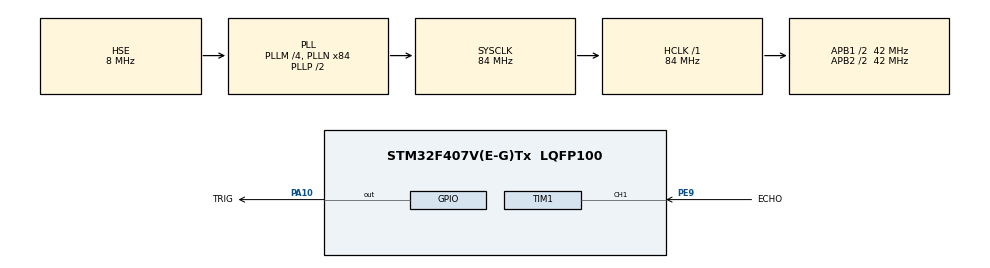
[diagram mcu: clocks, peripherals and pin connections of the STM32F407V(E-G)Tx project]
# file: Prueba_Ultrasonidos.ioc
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Mcu.Family=STM32F4
Mcu.Name=STM32F407V(E-G)Tx
Mcu.Package=LQFP100
NVIC.PriorityGroup=NVIC_PRIORITYGROUP_0
NVIC.TIM1_CC_IRQn=true\:0\:0\:false\:false\:true\:true\:true
PA10.GPIO_Label=TRIG
PA10.Signal=GPIO_Output
PE9.GPIO_Label=ECHO
PE9.Signal=S_TIM1_CH1
PH0-OSC_IN.Mode=HSE-External-Oscillator
PH0-OSC_IN.Signal=RCC_OSC_IN
PH1-OSC_OUT.Mode=HSE-External-Oscillator
PH1-OSC_OUT.Signal=RCC_OSC_OUT
ProjectManager.HeapSize=0x200
ProjectManager.StackSize=0x400
ProjectManager.TargetToolchain=STM32CubeIDE
RCC.48MHZClocksFreq_Value=24000000
RCC.AHBFreq_Value=84000000
RCC.APB1CLKDivider=RCC_HCLK_DIV2
RCC.APB1Freq_Value=42000000
RCC.APB1TimFreq_Value=84000000
RCC.APB2CLKDivider=RCC_HCLK_DIV2
RCC.APB2Freq_Value=42000000
RCC.APB2TimFreq_Value=84000000
RCC.CortexFreq_Value=84000000
RCC.HCLKFreq_Value=84000000
RCC.HSE_VALUE=8000000
RCC.HSI_VALUE=16000000
RCC.LSE_VALUE=32768
RCC.PLLM=4
RCC.PLLN=84
RCC.PLLQ=7
RCC.PLLSourceVirtual=RCC_PLLSOURCE_HSE
RCC.SYSCLKFreq_VALUE=84000000
RCC.SYSCLKSource=RCC_SYSCLKSOURCE_PLLCLK
RCC.VCOOutputFreq_Value=168000000
SH.S_TIM1_CH1.0=TIM1_CH1,Input_Capture1_from_TI1
TIM1.Channel-Input_Capture1_from_TI1=TIM_CHANNEL_1
TIM1.Period=65535-1
TIM1.Prescaler=84-1
board=STM32F407G-DISC1

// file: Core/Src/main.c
/* USER CODE BEGIN Header */
/**
  ******************************************************************************
  * @file           : main.c
  * @brief          : Main program body
  ******************************************************************************
  * @attention
  *
  * <h2><center>&copy; Copyright (c) 2021 STMicroelectronics.
  * All rights reserved.</center></h2>
  *
  * This software component is licensed by ST under BSD 3-Clause license,
  * the "License"; You may not use this file except in compliance with the
  * License. You may obtain a copy of the License at:
  *                        opensource.org/licenses/BSD-3-Clause
  *
  ******************************************************************************
  */
/* USER CODE END Header */
#include "main.h"

TIM_HandleTypeDef htim1;

void SystemClock_Config(void);
static void MX_GPIO_Init(void);
static void MX_TIM1_Init(void);

/* USER CODE BEGIN 0 */
float dist  = 0;

float calcularDistancia(uint64_t time)
{
	const float Vsonido = 340.0f;	// Velocidad sonido = 340m/s
	float dist = (float)time * Vsonido/2.0f / 10000.0f;	// El 1/10000 es por el cambio de conversion de s a us y de m a cm
	return dist;	// En cm
}

void HAL_TIM_IC_CaptureCallback(TIM_HandleTypeDef *htim)
{
	static uint64_t timeRise = 0, timeFall = 0, timeDif = 0;
	static uint8_t EdgeCapture = 0;	// 0 si va a detectar flanco de subida, 1 si va a detectar falcno de bajada

	if (!EdgeCapture)	// Si se va a detectar el flanco de subida
	{
		EdgeCapture = 1;  // Se cambia para detectar despues el flanco de bajada

		timeRise = HAL_TIM_ReadCapturedValue(htim, TIM_CHANNEL_1);	// Se guarda el instsnte de tiempo en el que se ha alcanzado el flanco de subida

		__HAL_TIM_SET_CAPTUREPOLARITY(htim, TIM_CHANNEL_1, TIM_INPUTCHANNELPOLARITY_FALLING);	// Cambio del tipo de flanco para detectar flancos de bajada
	}
	else	// Si se va a detectar el flanco de bajada
	{
		EdgeCapture = 0;	// Se cambia para detectar otro flanco de subida

		timeFall = HAL_TIM_ReadCapturedValue(htim, TIM_CHANNEL_1);  // Se guarda el instsnte de tiempo en el que se ha alcanzado el flanco de bajada

		__HAL_TIM_SET_COUNTER(htim, 0);	// Se pone a cero el contador de tiempo para la siguiente deteccion del flanco de subida
		__HAL_TIM_SET_CAPTUREPOLARITY(htim, TIM_CHANNEL_1, TIM_INPUTCHANNELPOLARITY_RISING);	// Cambio del tipo de flanco para detectar flancos de subida

		timeDif = timeFall - timeRise;	// El tiempo necesario para calcular la distancia es la resta del tiempo de flancos
		dist = calcularDistancia(timeDif);	// Se calcula la distancia en cm
	}
}

void leerUltrasonido(GPIO_TypeDef* GPIOx, uint16_t GPIO_Pin)
{
	HAL_GPIO_WritePin(GPIOx, GPIO_Pin, 1);	// Activar TRIG
	HAL_Delay(0.01);  // Esperar 10 us = 0.01 ms
	HAL_GPIO_WritePin(GPIOx, GPIO_Pin, 0);	// Desactivar TRIG
}

/* USER CODE END 0 */

int main(void)
{

  /* MCU Configuration--------------------------------------------------------*/

  /* Reset of all peripherals, Initializes the Flash interface and the Systick. */
  HAL_Init();

  /* Configure the system clock */
  SystemClock_Config();

  /* Initialize all configured peripherals */
  MX_GPIO_Init();
  MX_TIM1_Init();
  /* USER CODE BEGIN 2 */
  HAL_TIM_IC_Start_IT(&htim1, TIM_CHANNEL_1);
  /* USER CODE END 2 */

  /* Infinite loop */
  while (1)
  {

    /* USER CODE BEGIN 3 */
	leerUltrasonido(GPIOA, GPIO_PIN_10);	// Leer Ultrasonido conectado a pin A10
	HAL_Delay(100);	// Espera para volver a disparar, NO menor a 100ms !!!

  }
  /* USER CODE END 3 */
}

void SystemClock_Config(void)
{
  RCC_OscInitTypeDef RCC_OscInitStruct = {0};
  RCC_ClkInitTypeDef RCC_ClkInitStruct = {0};

  /** Configure the main internal regulator output voltage
  */
  __HAL_RCC_PWR_CLK_ENABLE();
  __HAL_PWR_VOLTAGESCALING_CONFIG(PWR_REGULATOR_VOLTAGE_SCALE1);
  /** Initializes the RCC Oscillators according to the specified parameters
  * in the RCC_OscInitTypeDef structure.
  */
  RCC_OscInitStruct.OscillatorType = RCC_OSCILLATORTYPE_HSE;
  RCC_OscInitStruct.HSEState = RCC_HSE_ON;
  RCC_OscInitStruct.PLL.PLLState = RCC_PLL_ON;
  RCC_OscInitStruct.PLL.PLLSource = RCC_PLLSOURCE_HSE;
  RCC_OscInitStruct.PLL.PLLM = 4;
  RCC_OscInitStruct.PLL.PLLN = 84;
  RCC_OscInitStruct.PLL.PLLP = RCC_PLLP_DIV2;
  RCC_OscInitStruct.PLL.PLLQ = 7;
  if (HAL_RCC_OscConfig(&RCC_OscInitStruct) != HAL_OK)
  {
    Error_Handler();
  }
  /** Initializes the CPU, AHB and APB buses clocks
  */
  RCC_ClkInitStruct.ClockType = RCC_CLOCKTYPE_HCLK|RCC_CLOCKTYPE_SYSCLK
                              |RCC_CLOCKTYPE_PCLK1|RCC_CLOCKTYPE_PCLK2;
  RCC_ClkInitStruct.SYSCLKSource = RCC_SYSCLKSOURCE_PLLCLK;
  RCC_ClkInitStruct.AHBCLKDivider = RCC_SYSCLK_DIV1;
  RCC_ClkInitStruct.APB1CLKDivider = RCC_HCLK_DIV2;
  RCC_ClkInitStruct.APB2CLKDivider = RCC_HCLK_DIV2;

  if (HAL_RCC_ClockConfig(&RCC_ClkInitStruct, FLASH_LATENCY_2) != HAL_OK)
  {
    Error_Handler();
  }
}

static void MX_TIM1_Init(void)
{

  TIM_MasterConfigTypeDef sMasterConfig = {0};
  TIM_IC_InitTypeDef sConfigIC = {0};

  htim1.Instance = TIM1;
  htim1.Init.Prescaler = 84-1;
  htim1.Init.CounterMode = TIM_COUNTERMODE_UP;
  htim1.Init.Period = 65535-1;
  htim1.Init.ClockDivision = TIM_CLOCKDIVISION_DIV1;
  htim1.Init.RepetitionCounter = 0;
  htim1.Init.AutoReloadPreload = TIM_AUTORELOAD_PRELOAD_DISABLE;
  if (HAL_TIM_IC_Init(&htim1) != HAL_OK)
  {
    Error_Handler();
  }
  sMasterConfig.MasterOutputTrigger = TIM_TRGO_RESET;
  sMasterConfig.MasterSlaveMode = TIM_MASTERSLAVEMODE_DISABLE;
  if (HAL_TIMEx_MasterConfigSynchronization(&htim1, &sMasterConfig) != HAL_OK)
  {
    Error_Handler();
  }
  sConfigIC.ICPolarity = TIM_INPUTCHANNELPOLARITY_RISING;
  sConfigIC.ICSelection = TIM_ICSELECTION_DIRECTTI;
  sConfigIC.ICPrescaler = TIM_ICPSC_DIV1;
  sConfigIC.ICFilter = 0;
  if (HAL_TIM_IC_ConfigChannel(&htim1, &sConfigIC, TIM_CHANNEL_1) != HAL_OK)
  {
    Error_Handler();
  }

}

static void MX_GPIO_Init(void)
{
  GPIO_InitTypeDef GPIO_InitStruct = {0};

  /* GPIO Ports Clock Enable */
  __HAL_RCC_GPIOH_CLK_ENABLE();
  __HAL_RCC_GPIOE_CLK_ENABLE();
  __HAL_RCC_GPIOA_CLK_ENABLE();

  /*Configure GPIO pin Output Level */
  HAL_GPIO_WritePin(GPIOA, GPIO_PIN_10, GPIO_PIN_RESET);

  /*Configure GPIO pin : PA10 */
  GPIO_InitStruct.Pin = GPIO_PIN_10;
  GPIO_InitStruct.Mode = GPIO_MODE_OUTPUT_PP;
  GPIO_InitStruct.Pull = GPIO_NOPULL;
  GPIO_InitStruct.Speed = GPIO_SPEED_FREQ_LOW;
  HAL_GPIO_Init(GPIOA, &GPIO_InitStruct);

}

void Error_Handler(void)
{
  __disable_irq();
  while (1)
  {
  }
}
